# CMS32L032 register map
Vendor: CMS; Series: CMS32L032; File version: 1.2
CPU: CM0+ r0p1, little endian, no MPU, no FPU, VTOR, 2 interrupt priority bits
Registers are 8-bit, read-write, reset 0x0 unless marked. A register's access mark holds for its fields unless they carry their own. Offsets are from the block's base; [hi:lo] are bit positions; {n}, {i} and the like mark numbered series; 'fields as' and 'values as' point back to an identical list.

## RST — Reset Function
Base 0x40020420
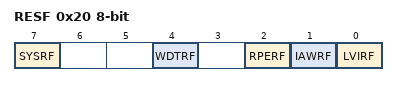
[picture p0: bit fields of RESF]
0x20 RESF ro — Reset flag register
  [all] fields
    0=NONE (Internal reset request is not generated, or the RESF register is cleared.); 1=DONE (Internal reset request is generated.)
  [7] SYSRF read-clears — Internal reset request by system reset request(AIRCR.SYSRESETREQ)
  [4] WDTRF read-clears — Internal reset request by watchdog timer(WDT)
  [2] RPERF read-clears — Internal reset request by RAM parity
  [1] IAWRF read-clears — Internal reset request by illegal-memory access
  [0] LVIRF read-clears — Internal reset request by voltage detector

## LVD — Voltage detector
Base 0x40020440
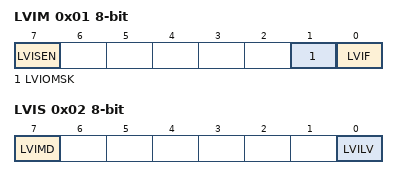
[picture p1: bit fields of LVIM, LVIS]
0x01 LVIM — Voltage detection register
  [7] LVISEN ro — Enable rewritting LVIS register
    0=Disable (Disabling of rewriting the LVIS register); 1=Enable (Enabling of rewriting the LVIS register)
  [1] LVIOMSK ro — Mask status flag of LVD output
    0=Invalid (Mask of LVD output is invalid); 1=Valid (Mask of LVD output is valid)
  [0] LVIF ro — Voltage detection flag
    0=GE (Supply voltage (VDD) greater or equal to detection voltage (VLVD), or when LVD is off); 1=LT (Supply voltage (VDD) less than detection voltage (VLVD))
0x02 LVIS — Voltage detection level register
  [7] LVIMD — Operation mode of voltage detection
    0=IRQ (interrupt mode); 1=reset mode
  [0] LVILV — LVD detection level
    0=High-voltage detection level (VLVDH); 1=Low (Low-voltage detection level (VLVDL or VLVD))

## PORT — Port functions
Base 0x40040000
{0x0+i} P{i} (i=0..3) — Port register {i}
{0x20+i} PM{i} reset 0xFF (i=0..3) — Port mode register {i}
0x30 PU0 — Pull-up resistor option register 0
0x31 PU1 reset 0x1 — Pull-up resistor option register 1
0x32 PU2 reset 0x40 — Pull-up resistor option register 2
0x33 PU3 — Pull-up resistor option register 3
{0x40+i} PD{i} (i=0..3) — Pull-down resistor option register {i}
{0x50+i} POM{i} (i=0..3) — Port output mode register {i}
0x60 PMC0 reset 0xF8 — Port mode control register 0
0x61 PMC1 reset 0xFF — Port mode control register 1
0x62 PMC2 reset 0xFC — Port mode control register 2
0x63 PMC3 reset 0x3F — Port mode control register 3
{0x70+i} PSET{i} (i=0..3) — Port set register {i}
{0x80+i} PCLR{i} (i=0..3) — Port clear register {i}
{0x90+i} PREAD{i} (i=0..3) — Port read register 0
{0x800+2i} P{i:02}CFG (i=0..2) — Alterate Output Function configuration register
  [5:0] CFG
    0=GPIO (Port used as GPIO); {v}=INTP{v-2} (Port used as INTP{v-2}) (v=2..5); {v}=TI{v-6:02} (Port used as TI{v-6:02}) (v=6..9); {v}=TI{v} (Port used as TI{v}) (v=10..13); {v}=TO{v-14:02} (Port used as TO{v-14:02}) (v=14..17); {v}=TO{v-8} (Port used as TO{v-8}) (v=18..21); 22=SCLA0 (Port used as SCLA0); 23=SDA0 (Port used as SDA0); 24=CLKBUZ0 (Port used as CLKBUZ0); 25=CLKBUZ1 (Port used as CLKBUZ1); 26=RTC1HZ (Port used as RTC1HZ); 28=SPI_SS (Port used as SPI_SS); 29=SPI_MOSI (Port used as SPI_MOSI); 30=SPI_MISO (Port used as SPI_MISO); 31=SPI_CLK (Port used as SPI_CLK); 38=SS00 (Port used as SS00); 39=SS10 (Port used as SS10); 40=SCLK00 (Port used as SCLK00 output); 41=SCLK01 (Port used as SCLK01 output); 42=SCLK10 (Port used as SCLK10 output); 43=SCLK11 (Port used as SCLK11 output); 44=SDI00/RXD0 (Port used as SDI00/RXD0 output); 45=SDI01 (Port used as SDI01 output); 46=SDI10/RXD1 (Port used as SDI10/RXD1 output); 47=SDI11 (Port used as SDI11 output); 48=SDO00/TxD0 (Port used as SDO00/TxD0); 49=SDO01 (Port used as SDO01); 50=SDO10/TXD1 (Port used as SDO10/TXD1); 51=SDO11 (Port used as SDO11); {v}=EPWMO{v-56:02} (Port used as EPWMO{v-56:02}) (v=56..63)
{0x7FC+2i} P{i}CFG (i=10..13) — Alterate Output Function configuration register
  fields as P00CFG
{0x7F8+2i} P{i}CFG (i=20..26) — Alterate Output Function configuration register
  fields as P00CFG
{0x7F4+2i} P{i}CFG (i=30..37) — Alterate Output Function configuration register
  fields as P00CFG
0x87B PMS (reset mask 0x1) — Port mode select register

## Notices in the file
Copyright (C) 2012-2014 ARM Limited. All rights reserved.
Purpose: System Viewer Description (SVD) Example (Schema Version 1.1)
This is a description of a none-existent and incomplete device
for demonstration purposes only.
Redistribution and use in source and binary forms, with or without
modification, are permitted provided that the following conditions are met:
- Redistributions of source code must retain the above copyright
notice, this list of conditions and the following disclaimer.
- Redistributions in binary form must reproduce the above copyright
notice, this list of conditions and the following disclaimer in the
documentation and/or other materials provided with the distribution.
- Neither the name of ARM nor the names of its contributors may be used
to endorse or promote products derived from this software without
specific prior written permission.
THIS SOFTWARE IS PROVIDED BY THE COPYRIGHT HOLDERS AND CONTRIBUTORS "AS IS"
AND ANY EXPRESS OR IMPLIED WARRANTIES, INCLUDING, BUT NOT LIMITED TO, THE
IMPLIED WARRANTIES OF MERCHANTABILITY AND FITNESS FOR A PARTICULAR PURPOSE
ARE DISCLAIMED. IN NO EVENT SHALL COPYRIGHT HOLDERS AND CONTRIBUTORS BE
LIABLE FOR ANY DIRECT, INDIRECT, INCIDENTAL, SPECIAL, EXEMPLARY, OR
CONSEQUENTIAL DAMAGES (INCLUDING, BUT NOT LIMITED TO, PROCUREMENT OF
SUBSTITUTE GOODS OR SERVICES; LOSS OF USE, DATA, OR PROFITS; OR BUSINESS
INTERRUPTION) HOWEVER CAUSED AND ON ANY THEORY OF LIABILITY, WHETHER IN
CONTRACT, STRICT LIABILITY, OR TORT (INCLUDING NEGLIGENCE OR OTHERWISE)
ARISING IN ANY WAY OUT OF THE USE OF THIS SOFTWARE, EVEN IF ADVISED OF THE
POSSIBILITY OF SUCH DAMAGE.
